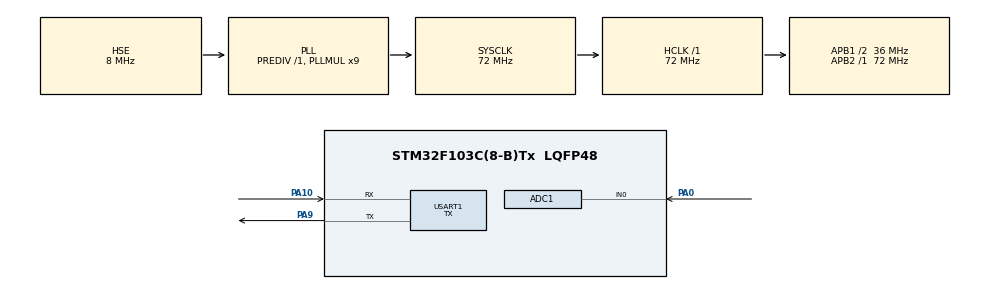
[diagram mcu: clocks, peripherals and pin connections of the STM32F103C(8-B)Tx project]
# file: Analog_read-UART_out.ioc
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ADC1.Channel-0\#ChannelRegularConversion=ADC_CHANNEL_0
ADC1.EnableInjectedConversion=DISABLE
ADC1.ExternalTrigConv=ADC_EXTERNALTRIGCONV_T3_TRGO
ADC1.NbrOfConversionFlag=1
ADC1.Rank-0\#ChannelRegularConversion=1
ADC1.SamplingTime-0\#ChannelRegularConversion=ADC_SAMPLETIME_1CYCLE_5
ADC1.master=1
Dma.ADC1.0.Direction=DMA_PERIPH_TO_MEMORY
Dma.ADC1.0.Instance=DMA1_Channel1
Dma.ADC1.0.MemDataAlignment=DMA_MDATAALIGN_HALFWORD
Dma.ADC1.0.MemInc=DMA_MINC_ENABLE
Dma.ADC1.0.Mode=DMA_CIRCULAR
Dma.ADC1.0.PeriphDataAlignment=DMA_PDATAALIGN_HALFWORD
Dma.ADC1.0.PeriphInc=DMA_PINC_DISABLE
Dma.ADC1.0.Priority=DMA_PRIORITY_LOW
Dma.Request0=ADC1
Dma.Request1=USART1_TX
Dma.USART1_TX.1.Direction=DMA_MEMORY_TO_PERIPH
Dma.USART1_TX.1.Instance=DMA1_Channel4
Dma.USART1_TX.1.MemDataAlignment=DMA_MDATAALIGN_BYTE
Dma.USART1_TX.1.MemInc=DMA_MINC_ENABLE
Dma.USART1_TX.1.Mode=DMA_NORMAL
Dma.USART1_TX.1.PeriphDataAlignment=DMA_PDATAALIGN_BYTE
Dma.USART1_TX.1.PeriphInc=DMA_PINC_DISABLE
Dma.USART1_TX.1.Priority=DMA_PRIORITY_MEDIUM
Mcu.Family=STM32F1
Mcu.Name=STM32F103C(8-B)Tx
Mcu.Package=LQFP48
NVIC.ADC1_2_IRQn=true\:0\:0\:false\:false\:true\:true\:true\:true
NVIC.DMA1_Channel1_IRQn=true\:0\:0\:false\:false\:true\:false\:true\:true
NVIC.DMA1_Channel4_IRQn=true\:0\:0\:false\:false\:true\:false\:true\:true
NVIC.PriorityGroup=NVIC_PRIORITYGROUP_4
NVIC.USART1_IRQn=true\:0\:0\:false\:false\:true\:true\:true\:true
PA0-WKUP.Signal=ADCx_IN0
PA10.Mode=Asynchronous
PA10.Signal=USART1_RX
PA13.Mode=Serial_Wire
PA13.Signal=SYS_JTMS-SWDIO
PA14.Mode=Serial_Wire
PA14.Signal=SYS_JTCK-SWCLK
PA9.Mode=Asynchronous
PA9.Signal=USART1_TX
PD0-OSC_IN.Mode=HSE-External-Oscillator
PD0-OSC_IN.Signal=RCC_OSC_IN
PD1-OSC_OUT.Mode=HSE-External-Oscillator
PD1-OSC_OUT.Signal=RCC_OSC_OUT
ProjectManager.HeapSize=0x200
ProjectManager.StackSize=0x400
ProjectManager.TargetToolchain=STM32CubeIDE
RCC.ADCPresc=RCC_ADCPCLK2_DIV6
RCC.AHBFreq_Value=72000000
RCC.APB1CLKDivider=RCC_HCLK_DIV2
RCC.APB1Freq_Value=36000000
RCC.APB1TimFreq_Value=72000000
RCC.APB2Freq_Value=72000000
RCC.APB2TimFreq_Value=72000000
RCC.HCLKFreq_Value=72000000
RCC.PLLMUL=RCC_PLL_MUL9
RCC.PLLSourceVirtual=RCC_PLLSOURCE_HSE
RCC.SYSCLKFreq_VALUE=72000000
RCC.SYSCLKSource=RCC_SYSCLKSOURCE_PLLCLK
RCC.USBFreq_Value=72000000
SH.ADCx_IN0.0=ADC1_IN0,IN0
TIM3.Period=99
TIM3.Prescaler=7199
TIM3.TIM_MasterOutputTrigger=TIM_TRGO_UPDATE
USART1.Mode=MODE_TX
USART1.VirtualMode=VM_ASYNC
VP_TIM3_VS_ClockSourceINT.Mode=Internal
board=custom

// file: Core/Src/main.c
/* USER CODE BEGIN Header */
/**
  ******************************************************************************
  * @file           : main.c
  * @brief          : Main program body
  ******************************************************************************
  * @attention
  *
  * Copyright (c) 2025 STMicroelectronics.
  * All rights reserved.
  *
  * This software is licensed under terms that can be found in the LICENSE file
  * in the root directory of this software component.
  * If no LICENSE file comes with this software, it is provided AS-IS.
  *
  ******************************************************************************
  */
/* USER CODE END Header */
#include "main.h"
#include <stdio.h>

ADC_HandleTypeDef hadc1;
DMA_HandleTypeDef hdma_adc1;

TIM_HandleTypeDef htim3;

UART_HandleTypeDef huart1;
DMA_HandleTypeDef hdma_usart1_tx;

/* USER CODE BEGIN PV */

uint16_t buffer[1];
volatile uint8_t flag = 0;
volatile uint8_t uart_busy = 0;
char msg[64];

/* USER CODE END PV */

void SystemClock_Config(void);
static void MX_GPIO_Init(void);
static void MX_DMA_Init(void);
static void MX_ADC1_Init(void);
static void MX_TIM3_Init(void);
static void MX_USART1_UART_Init(void);

int main(void)
{

  /* MCU Configuration--------------------------------------------------------*/

  /* Reset of all peripherals, Initializes the Flash interface and the Systick. */
  HAL_Init();

  /* Configure the system clock */
  SystemClock_Config();

  /* Initialize all configured peripherals */
  MX_GPIO_Init();
  MX_DMA_Init();
  MX_ADC1_Init();
  MX_TIM3_Init();
  MX_USART1_UART_Init();
  /* USER CODE BEGIN 2 */

  HAL_TIM_Base_Start(&htim3);
  HAL_ADCEx_Calibration_Start(&hadc1);
  HAL_ADC_Start_DMA(&hadc1, (uint32_t*)buffer, 1);

  /* USER CODE END 2 */

  /* Infinite loop */
  while (1)
  {

    /* USER CODE BEGIN 3 */
	  /* USER CODE BEGIN 3 */
	  if (flag == 1 && uart_busy == 0)
	  {

	      flag = 0;
	      uart_busy = 1;

	      float voltage = (buffer[0] * 3.3f) / 4095.0f;

	      int len = sprintf(msg, "Raw: %d | Voltage: %.2f V\r\n", buffer[0], voltage);

	      HAL_UART_Transmit_DMA(&huart1, (uint8_t*)msg, len);

	  }
	  /* USER CODE END 3 */
  /* USER CODE END 3 */
}

}
void SystemClock_Config(void)
{
  RCC_OscInitTypeDef RCC_OscInitStruct = {0};
  RCC_ClkInitTypeDef RCC_ClkInitStruct = {0};
  RCC_PeriphCLKInitTypeDef PeriphClkInit = {0};

  /** Initializes the RCC Oscillators according to the specified parameters
  * in the RCC_OscInitTypeDef structure.
  */
  RCC_OscInitStruct.OscillatorType = RCC_OSCILLATORTYPE_HSE;
  RCC_OscInitStruct.HSEState = RCC_HSE_ON;
  RCC_OscInitStruct.HSEPredivValue = RCC_HSE_PREDIV_DIV1;
  RCC_OscInitStruct.HSIState = RCC_HSI_ON;
  RCC_OscInitStruct.PLL.PLLState = RCC_PLL_ON;
  RCC_OscInitStruct.PLL.PLLSource = RCC_PLLSOURCE_HSE;
  RCC_OscInitStruct.PLL.PLLMUL = RCC_PLL_MUL9;
  if (HAL_RCC_OscConfig(&RCC_OscInitStruct) != HAL_OK)
  {
    Error_Handler();
  }

  /** Initializes the CPU, AHB and APB buses clocks
  */
  RCC_ClkInitStruct.ClockType = RCC_CLOCKTYPE_HCLK|RCC_CLOCKTYPE_SYSCLK
                              |RCC_CLOCKTYPE_PCLK1|RCC_CLOCKTYPE_PCLK2;
  RCC_ClkInitStruct.SYSCLKSource = RCC_SYSCLKSOURCE_PLLCLK;
  RCC_ClkInitStruct.AHBCLKDivider = RCC_SYSCLK_DIV1;
  RCC_ClkInitStruct.APB1CLKDivider = RCC_HCLK_DIV2;
  RCC_ClkInitStruct.APB2CLKDivider = RCC_HCLK_DIV1;

  if (HAL_RCC_ClockConfig(&RCC_ClkInitStruct, FLASH_LATENCY_2) != HAL_OK)
  {
    Error_Handler();
  }
  PeriphClkInit.PeriphClockSelection = RCC_PERIPHCLK_ADC;
  PeriphClkInit.AdcClockSelection = RCC_ADCPCLK2_DIV6;
  if (HAL_RCCEx_PeriphCLKConfig(&PeriphClkInit) != HAL_OK)
  {
    Error_Handler();
  }
}

static void MX_ADC1_Init(void)
{

  ADC_ChannelConfTypeDef sConfig = {0};

  /** Common config
  */
  hadc1.Instance = ADC1;
  hadc1.Init.ScanConvMode = ADC_SCAN_DISABLE;
  hadc1.Init.ContinuousConvMode = DISABLE;
  hadc1.Init.DiscontinuousConvMode = DISABLE;
  hadc1.Init.ExternalTrigConv = ADC_EXTERNALTRIGCONV_T3_TRGO;
  hadc1.Init.DataAlign = ADC_DATAALIGN_RIGHT;
  hadc1.Init.NbrOfConversion = 1;
  if (HAL_ADC_Init(&hadc1) != HAL_OK)
  {
    Error_Handler();
  }

  /** Configure Regular Channel
  */
  sConfig.Channel = ADC_CHANNEL_0;
  sConfig.Rank = ADC_REGULAR_RANK_1;
  sConfig.SamplingTime = ADC_SAMPLETIME_1CYCLE_5;
  if (HAL_ADC_ConfigChannel(&hadc1, &sConfig) != HAL_OK)
  {
    Error_Handler();
  }

}

static void MX_TIM3_Init(void)
{

  TIM_ClockConfigTypeDef sClockSourceConfig = {0};
  TIM_MasterConfigTypeDef sMasterConfig = {0};

  htim3.Instance = TIM3;
  htim3.Init.Prescaler = 7199;
  htim3.Init.CounterMode = TIM_COUNTERMODE_UP;
  htim3.Init.Period = 99;
  htim3.Init.ClockDivision = TIM_CLOCKDIVISION_DIV1;
  htim3.Init.AutoReloadPreload = TIM_AUTORELOAD_PRELOAD_DISABLE;
  if (HAL_TIM_Base_Init(&htim3) != HAL_OK)
  {
    Error_Handler();
  }
  sClockSourceConfig.ClockSource = TIM_CLOCKSOURCE_INTERNAL;
  if (HAL_TIM_ConfigClockSource(&htim3, &sClockSourceConfig) != HAL_OK)
  {
    Error_Handler();
  }
  sMasterConfig.MasterOutputTrigger = TIM_TRGO_UPDATE;
  sMasterConfig.MasterSlaveMode = TIM_MASTERSLAVEMODE_DISABLE;
  if (HAL_TIMEx_MasterConfigSynchronization(&htim3, &sMasterConfig) != HAL_OK)
  {
    Error_Handler();
  }

}

static void MX_USART1_UART_Init(void)
{

  huart1.Instance = USART1;
  huart1.Init.BaudRate = 115200;
  huart1.Init.WordLength = UART_WORDLENGTH_8B;
  huart1.Init.StopBits = UART_STOPBITS_1;
  huart1.Init.Parity = UART_PARITY_NONE;
  huart1.Init.Mode = UART_MODE_TX;
  huart1.Init.HwFlowCtl = UART_HWCONTROL_NONE;
  huart1.Init.OverSampling = UART_OVERSAMPLING_16;
  if (HAL_UART_Init(&huart1) != HAL_OK)
  {
    Error_Handler();
  }

}

static void MX_DMA_Init(void)
{

  /* DMA controller clock enable */
  __HAL_RCC_DMA1_CLK_ENABLE();

  /* DMA interrupt init */
  /* DMA1_Channel1_IRQn interrupt configuration */
  HAL_NVIC_SetPriority(DMA1_Channel1_IRQn, 0, 0);
  HAL_NVIC_EnableIRQ(DMA1_Channel1_IRQn);
  /* DMA1_Channel4_IRQn interrupt configuration */
  HAL_NVIC_SetPriority(DMA1_Channel4_IRQn, 0, 0);
  HAL_NVIC_EnableIRQ(DMA1_Channel4_IRQn);

}

static void MX_GPIO_Init(void)
{

  /* GPIO Ports Clock Enable */
  __HAL_RCC_GPIOD_CLK_ENABLE();
  __HAL_RCC_GPIOA_CLK_ENABLE();

}

/* USER CODE BEGIN 4 */
void HAL_ADC_ConvCpltCallback(ADC_HandleTypeDef* hadc)
{
    if (hadc->Instance == ADC1)
    {

       flag = 1;
    }
}
void HAL_UART_TxCpltCallback(UART_HandleTypeDef *huart)
{
    if (huart->Instance == USART1)
    {
    	uart_busy = 0;
    }
}

/* USER CODE END 4 */

void Error_Handler(void)
{
  __disable_irq();
  while (1)
  {
  }
}
